# GD32M53x register map
File version: 1.0
CPU: CM33 r2p1, little endian, MPU, FPU, DSP, 4 interrupt priority bits
Registers are 32-bit, read-write, reset 0x0 unless marked. A register's access mark holds for its fields unless they carry their own. Offsets are from the block's base; [hi:lo] are bit positions; {n}, {i} and the like mark numbered series.

## GPTIMER0 — General purpose timer
Base 0x40016000
Same registers: GPTIMER1 0x40016100
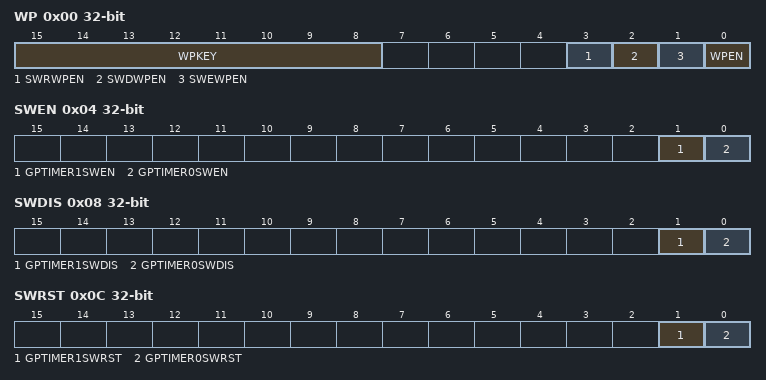
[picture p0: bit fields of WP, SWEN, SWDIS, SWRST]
0x00 WP access per field — Write-protect register
  [15:8] WPKEY wo — Write protection key
  [3] SWRWPEN rw — GPTIMERx_SWRST write protection enable
  [2] SWDWPEN rw — GPTIMERx_SWDIS write protection enable
  [1] SWEWPEN rw — GPTIMERx_SWEN write protection enable
  [0] WPEN rw — Register write protection enable
0x04 SWEN — Software enable register
  [1] GPTIMER1SWEN — GPTIMER1 counter software enable
  [0] GPTIMER0SWEN — GPTIMER0 counter software enable
0x08 SWDIS — Software disable register
  [1] GPTIMER1SWDIS — GPTIMER1 counter software disable
  [0] GPTIMER0SWDIS — GPTIMER0 counter software disable
0x0C SWRST — Software reset register
  [1] GPTIMER1SWRST — GPTIMER1 counter software reset
  [0] GPTIMER0SWRST — GPTIMER0 counter software reset
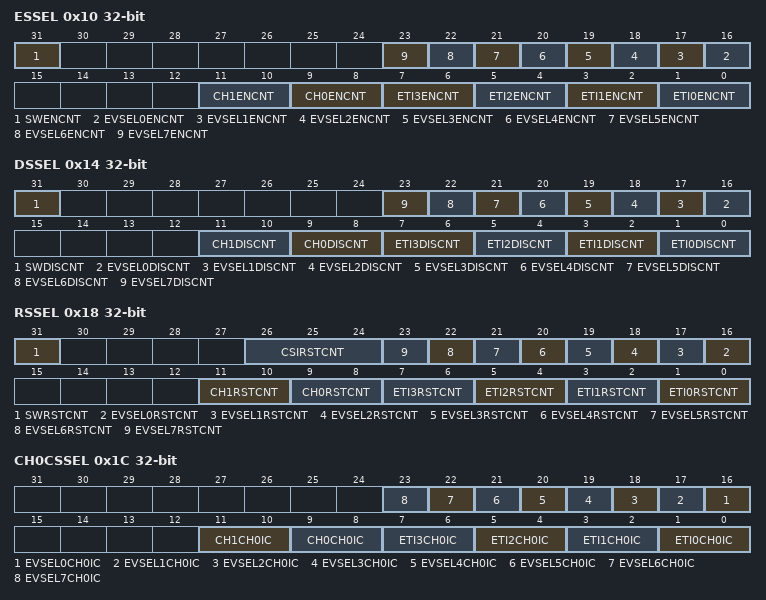
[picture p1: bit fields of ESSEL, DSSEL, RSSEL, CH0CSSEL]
0x10 ESSEL — Counter enable source selection register
  [31] SWENCNT — The software signal enable counter function enable
  [n+16] EVSEL{n}ENCNT (n=0..7) — The EVSEL{n} signal enable counter function enable
  [11:10] CH1ENCNT — The channel 1 signal edge enable counter function enable
  [9:8] CH0ENCNT — The channel 0 signal edge enable counter function enable
  [2n+1:2n] ETI{n}ENCNT (n=0..3) — The ETI{n} signal edge enable counter function enable
0x14 DSSEL — Counter disable source selection register
  [31] SWDISCNT — The software signal disable counter function enable
  [n+16] EVSEL{n}DISCNT (n=0..7) — The EVSEL{n} signal disable counter function enable
  [11:10] CH1DISCNT — The channel 1 signal edge disable counter function enable
  [9:8] CH0DISCNT — The channel 0 signal edge disable counter function enable
  [2n+1:2n] ETI{n}DISCNT (n=0..3) — The ETI{n} signal edge disable counter function enable
0x18 RSSEL — Counter reset source selection register
  [31] SWRSTCNT — The software signal reset counter function enable
  [26:24] CSIRSTCNT — The compares match, synchronous reset or input capture reset counter function enable
  [n+16] EVSEL{n}RSTCNT (n=0..7) — The EVSEL{n} signal reset counter function enable
  [11:10] CH1RSTCNT — The channel 1 signal edge reset counter function enable
  [9:8] CH0RSTCNT — The channel 0 signal edge reset counter function enable
  [2n+1:2n] ETI{n}RSTCNT (n=0..3) — The ETI{n} signal edge reset counter function enable
0x1C CH0CSSEL — Channel 0 capture source selection register
  [n+16] EVSEL{n}CH0IC (n=0..7) — The EVSEL{n} signal as the channel 0 input capture source enable
  [11:10] CH1CH0IC — The channel 1 signal edge as the channel 0 input capture source enable
  [9:8] CH0CH0IC — The channel 0 signal edge as the channel 0 input capture source enable
  [2n+1:2n] ETI{n}CH0IC (n=0..3) — The ETI{n} signal edge as the channel 0 input capture source enable
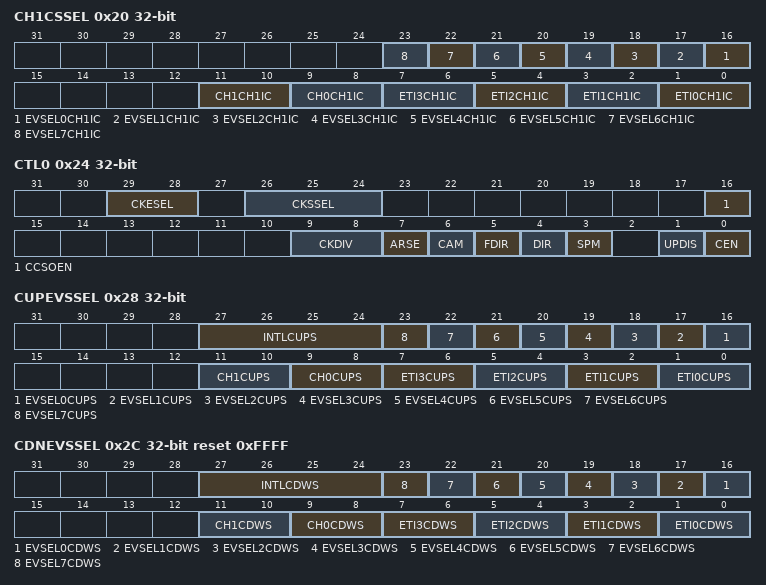
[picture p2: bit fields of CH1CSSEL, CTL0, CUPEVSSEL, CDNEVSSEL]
0x20 CH1CSSEL — Channel 1 capture source selection register
  [n+16] EVSEL{n}CH1IC (n=0..7) — The EVSEL{n} signal as the channel 1 input capture source enable
  [11:10] CH1CH1IC — The channel 1 signal edge as the channel 1 input capture source enable
  [9:8] CH0CH1IC — The channel 0 signal edge as the channel 1 input capture source enable
  [2n+1:2n] ETI{n}CH1IC (n=0..3) — The ETI{n} signal edge as the channel 1 input capture source enable
0x24 CTL0 — Control register 0
  [29:28] CKESEL — Effective edge selection when ETIx(x = 0, 1, 2, 3) is selected as the clock.
  [26:24] CKSSEL — Clock source selection
  [16] CCSOEN — The counter cycle synchronization signal output enable
  [9:8] CKDIV — Clock division
  [7] ARSE — Auto-reload shadow enable
  [6] CAM — Counter align mode selection
  [5] FDIR — Force the counting direction
  [4] DIR — Direction
  [3] SPM — Single pulse mode
  [1] UPDIS — Update event disable
  [0] CEN — Counter enable
0x28 CUPEVSSEL — Count up event source selection register
  [27:24] INTLCUPS — The input level as the count up event source function enable
  [n+16] EVSEL{n}CUPS (n=0..7) — The EVSEL{n} signal as the count up event source function enable
  [11:10] CH1CUPS — The channel 1 signal edge as the count up event source function enable
  [9:8] CH0CUPS — The channel 0 signal edge as the count up event source function enable
  [2n+1:2n] ETI{n}CUPS (n=0..3) — The ETI{n} signal edge as the count up event source function enable
0x2C CDNEVSSEL reset 0xFFFF — Count down event source selection register
  [27:24] INTLCDWS — The input level as the count down event source function enable
  [n+16] EVSEL{n}CDWS (n=0..7) — The EVSEL{n} signal as the count down event source function enable
  [11:10] CH1CDWS — The channel 1 signal edge as the count down event source function enable
  [9:8] CH0CDWS — The channel 0 signal edge as the count down event source function enable
  [2n+1:2n] ETI{n}CDWS (n=0..3) — The ETI{n} signal edge as the count down event source function enable
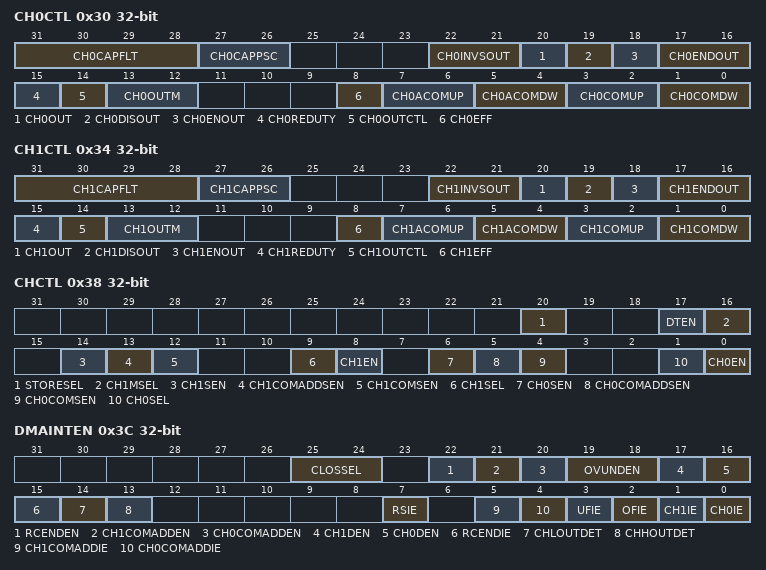
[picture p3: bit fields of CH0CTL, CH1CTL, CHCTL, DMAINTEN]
0x30 CH0CTL — Channel 0 control register
  [31:28] CH0CAPFLT — Channel 0 input capture filter control
  [27:26] CH0CAPPSC — Channel 0 input capture prescaler
  [22:21] CH0INVSOUT — Channel 0 invalid level setting when GTOC sends a stop output request
  [20] CH0OUT — Channel 0 output level selection when counter enable or disable.
  [19] CH0DISOUT — Channel 0 output level selection when counter disable
  [18] CH0ENOUT — Channel 0 output initial level selection when counter enable.
  [17:16] CH0ENDOUT — Channel 0 output level selection at the end of the period
  [15] CH0REDUTY — Channel 0 output level selection when counter release from 0% or 100% duty cycle mode
  [14] CH0OUTCTL — Channel 0 output control setting
  [13:12] CH0OUTM — Channel 0 output mode
  [8] CH0EFF — Channel 0 output control is effective or not when the end of the cycle and comparison match occur simultaneously.
  [7:6] CH0ACOMUP — Channel 0 additional compare match output level control when counter count up
  [5:4] CH0ACOMDW — Channel 0 additional compare match output level control when counter count down
  [3:2] CH0COMUP — Channel 0 compare match output level control when counter count up
  [1:0] CH0COMDW — Channel 0 compare match output level control when counter count down
0x34 CH1CTL — Channel 1 control register
  [31:28] CH1CAPFLT — Channel 1 input capture filter control
  [27:26] CH1CAPPSC — Channel 1 input capture prescaler
  [22:21] CH1INVSOUT — Channel 1 invalid level setting when GTOC sends a stop output request
  [20] CH1OUT — Channel 1 output level selection when counter enable or disable.
  [19] CH1DISOUT — Channel 1 output level selection when counter disable
  [18] CH1ENOUT — Channel 1 output initial level selection when counter enable.
  [17:16] CH1ENDOUT — Channel 1 output level selection at the end of the period
  [15] CH1REDUTY — Channel 1 output level selection when counter release from 0% or 100% duty cycle mode
  [14] CH1OUTCTL — Channel 1 output control setting
  [13:12] CH1OUTM — Channel 1 output mode
  [8] CH1EFF — Channel 1 output control is effective or not when the end of the cycle and comparison match occur simultaneously.
  [7:6] CH1ACOMUP — Channel 1 additional compare match output level control when counter count up
  [5:4] CH1ACOMDW — Channel 1 additional compare match output level control when counter count down
  [3:2] CH1COMUP — Channel 1 compare match output level control when counter count up
  [1:0] CH1COMDW — Channel 1 compare match output level control when counter count down
0x38 CHCTL — Channel control register
  [20] STORESEL — Stop output recovery time selection
  [17] DTEN — The insertion of the dead time enable
  [16] CH1MSEL — Channel 1 mode selection
  [14] CH1SEN — Channel 1 output shadow enable
  [13] CH1COMADDSEN — Channel 1 additional compare output shadow enable
  [12] CH1COMSEN — Channel 1 compare output shadow enable
  [9] CH1SEL — Channel 1 capture/compare selection
  [8] CH1EN — Channel 1 capture/compare enable
  [6] CH0SEN — Channel 0 output shadow enable
  [5] CH0COMADDSEN — Channel 0 additional compare output shadow enable
  [4] CH0COMSEN — Channel 0 compare output shadow enable
  [1] CH0SEL — Channel 0 capture/compare select
  [0] CH0EN — Channel 0 capture/compare enable
0x3C DMAINTEN — DMA and interrupt enable register
  [25:24] CLOSSEL — Closing output source selection from GTOC
  [22] RCENDEN — Repetition count end DMA request enable
  [21] CH1COMADDEN — Channel 1 additional compare DMA request enable
  [20] CH0COMADDEN — Channel 0 additional compare DMA request enable
  [19:18] OVUNDEN — Counter overflow / underflow DMA request enable
  [17] CH1DEN — Channel 1 capture / compare DMA request enable
  [16] CH0DEN — Channel 0 capture / compare DMA request enable
  [15] RCENDIE — Repetition count end interrupt enable
  [14] CHLOUTDET — Channel 0 and channel 1 simultaneously output low level output off detection enable
  [13] CHHOUTDET — Channel 0 and channel 1 simultaneously output high level output off detection enable
  [7] RSIE — Reset interrupt enable
  [5] CH1COMADDIE — Channel 1 additional compare interrupt enable
  [4] CH0COMADDIE — Channel 0 additional compare interrupt enable
  [3] UFIE — Counter underflow interrupt enable
  [2] OFIE — Counter overflow interrupt enable
  [1] CH1IE — Channel 1 capture/compare interrupt enable
  [0] CH0IE — Channel 0 capture/compare interrupt enable
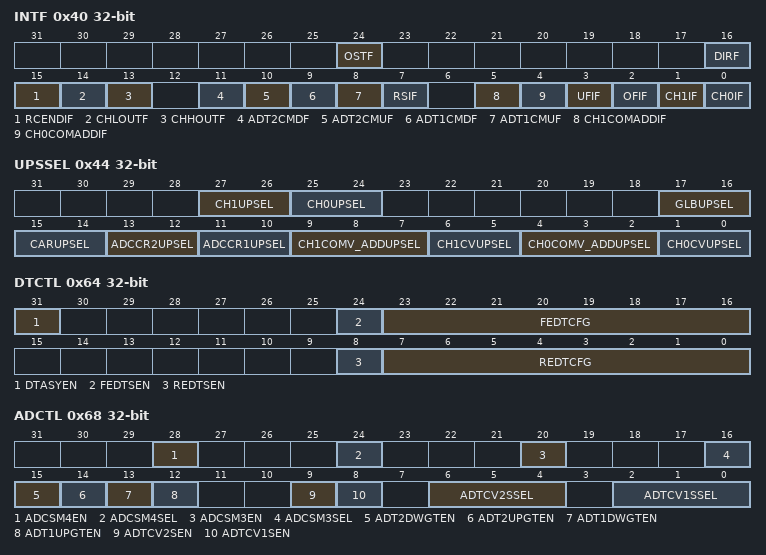
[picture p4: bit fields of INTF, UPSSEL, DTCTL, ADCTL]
0x40 INTF access per field — Interrupt flag register
  [24] OSTF ro — Output stop flag (Stop output source selected according to CLOSSEL[1:0] bit field)
  [16] DIRF ro — The counter direction flag
  [15] RCENDIF rw — Repetition count end interrupt flag
  [14] CHLOUTF ro — Channel 0 and channel 1 simultaneously output low level flag
  [13] CHHOUTF ro — Channel 0 and channel 1 simultaneously output high level flag
  [11] ADT2CMDF rw — ADTCV2[15:0] compare match (counting down only) flag.
  [10] ADT2CMUF rw — ADTCV2[15:0] compare match (counting up only) flag.
  [9] ADT1CMDF rw — ADTCV1[15:0] compare match (counting down only) flag.
  [8] ADT1CMUF rw — ADTCV1[15:0] compare match (counting up only) flag.
  [7] RSIF rw — Reset interrupt flag
  [5] CH1COMADDIF rw — Channel 1 additional compare interrupt flag.
  [4] CH0COMADDIF rw — Channel 0 additional compare interrupt flag.
  [3] UFIF rw — The counter underflow interrupt flag
  [2] OFIF rw — The counter overflow interrupt flag
  [1] CH1IF rw — Channel 1 capture/compare interrupt flag
  [0] CH0IF rw — Channel 0 capture/compare interrupt flag
0x44 UPSSEL — Update source selection register
  [27:26] CH1UPSEL — Channel 1 output mode update source selection.
  [25:24] CH0UPSEL — Channel 0 output mode update source selection.
  [17:16] GLBUPSEL — Global update mode update source selection.
  [15:14] CARUPSEL — The counter auto reload value update mode selection, used to set when the counter auto reload value will be automatically overloaded.
  [13:12] ADCCR2UPSEL — The ADC triggered comparison value 2 update mode selection.
  [11:10] ADCCR1UPSEL — The ADC triggered comparison value 1 update mode selection.
  [9:7] CH1COMV_ADDUPSEL — Channel 1 additional comparison value update mode selection.
  [6:5] CH1CVUPSEL — Channel 1 capture/compare value update mode selection.
  [4:2] CH0COMV_ADDUPSEL — Channel 0 additional comparison value update mode selection.
  [1:0] CH0CVUPSEL — Channel 0 capture/compare value update mode selection.
0x48 CNT — Counter register
  [15:0] CNT — This bit-field indicates the current counter value. Writing to this bit-field can change the value of the counter.
0x4C PSC — Prescaler register
  [15:0] PSC — Prescaler value of the counter clock
0x50 CAR — Counter auto reload register
  [15:0] CARL — Counter auto reload value
0x54 CH0CV — Channel 0 capture/compare value register
  [15:0] CH0VAL — Capture/compare value of channel 0
0x58 CH1CV — Channel 1 capture/compare value register
  [15:0] CH1VAL — Capture/compare value of channel 1
0x5C CH0COMV_ADD — Channel 0 additional compare value register
  [15:0] CH0COMVAL_ADD — Additional compare value of channel 0
0x60 CH1COMV_ADD — Channel 1 additional compare value register
  [15:0] CH1COMVAL_ADD — Additional compare value of channel 1
0x64 DTCTL — Dead-time control register
  [31] DTASYEN — Dead time asymmetric mode enable
  [24] FEDTSEN — The falling edge dead time shadow register is enabled.
  [23:16] FEDTCFG — The falling edge dead time configuration
  [8] REDTSEN — The rising edge dead time shadow register enable
  [7:0] REDTCFG — The rising edge dead time configuration
0x68 ADCTL — ADC trigger control register
  [28] ADCSM4EN — ADCSM4 pin output enable
  [24] ADCSM4SEL — Select the ADC trigger source connected to ADCSM4 pin
  [20] ADCSM3EN — ADCSM3 pin output enable
  [16] ADCSM3SEL — Select the ADC trigger source connected to ADCSM3 pin
  [15] ADT2DWGTEN — The ADTCV2[15:0] comparison match (count down only) generate trigger enable
  [14] ADT2UPGTEN — The ADTCV2[15:0] comparison match (count up only) generate trigger enable
  [13] ADT1DWGTEN — The ADTCV1[15:0] comparison match (count down only) generate trigger enable
  [12] ADT1UPGTEN — The ADTCV1[15:0] comparison match (count up only) generate trigger enable
  [9] ADTCV2SEN — The ADTCV2[15:0] shadow register enable
  [8] ADTCV1SEN — The ADTCV1[15:0] shadow register enable
  [6:4] ADTCV2SSEL — The ADC conversion request skipping source selection and the trigger signal generated by ADTCV2[15:0]
  [2:0] ADTCV1SSEL — The ADC conversion request skipping source selection and the trigger signal generated by ADTCV1[15:0]
0x6C ADCCR1 — ADC trigger compare value register 1
  [15:0] ADTCV1 — The ADC trigger compare value 1
0x70 ADCCR2 — ADC trigger compare value register 2
  [15:0] ADTCV2 — The ADC trigger compare value 2
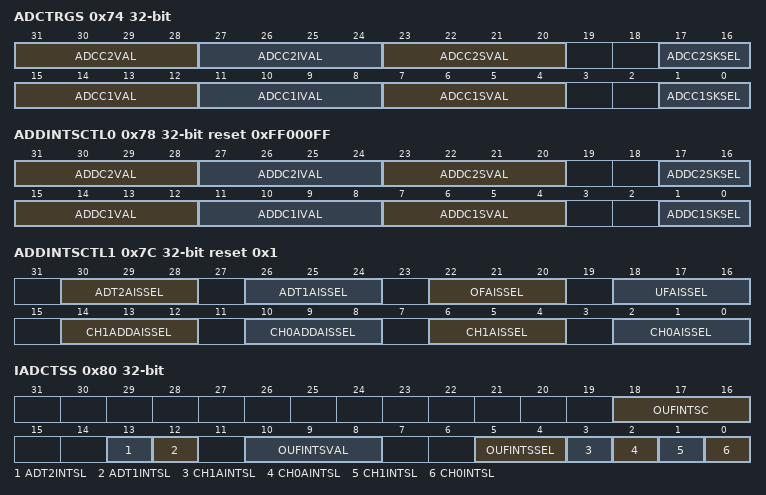
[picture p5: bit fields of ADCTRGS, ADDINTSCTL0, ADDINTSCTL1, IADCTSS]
0x74 ADCTRGS — ADC trigger skipping register
  [31:28] ADCC2VAL — This bit-field indicates the current ADC skipping counter 2 value.
  [27:24] ADCC2IVAL — The ADC skipping counter 2 Initial value
  [23:20] ADCC2SVAL — The ADC skipping counter 2 skipping value
  [17:16] ADCC2SKSEL — The ADC skipping counter 2 skipping source selection
  [15:12] ADCC1VAL — This bit-field indicates the current ADC skipping counter 1 value.
  [11:8] ADCC1IVAL — The ADC skipping counter 1 Initial value
  [7:4] ADCC1SVAL — The ADC skipping counter 1 skipping value
  [1:0] ADCC1SKSEL — The ADC skipping counter 1 skipping source selection
0x78 ADDINTSCTL0 reset 0xFF000FF — Additional interrupt skipping control register 0
  [31:28] ADDC2VAL — This bit-field indicates the current additional interrupt skipping counter 2 value.
  [27:24] ADDC2IVAL — The additional interrupt skipping counter 2 Initial value
  [23:20] ADDC2SVAL — The additional interrupt skipping counter 2 skipping value
  [17:16] ADDC2SKSEL — The additional interrupt skipping counter 2 skipping source selection
  [15:12] ADDC1VAL — This bit-field indicates the current additional interrupt skipping counter 1 value.
  [11:8] ADDC1IVAL — The additional interrupt skipping counter 1 Initial value
  [7:4] ADDC1SVAL — The additional interrupt skipping counter 1 skipping value
  [1:0] ADDC1SKSEL — The additional interrupt skipping counter 1 skipping source selection
0x7C ADDINTSCTL1 reset 0x1 — Additional interrupt skipping control register 1
  [30:28] ADT2AISSEL — The trigger signal generated by ADTCV2[15:0] additional interrupt skipping function selection.
  [26:24] ADT1AISSEL — The trigger signal generated by ADTCV1[15:0] additional interrupt skipping function selection.
  [22:20] OFAISSEL — Overflow additional interrupt skipping function selection.
  [18:16] UFAISSEL — Underflow additional interrupt skipping function selection.
  [14:12] CH1ADDAISSEL — The channel 1 additional value compare match additional interrupt skipping function selection.
  [10:8] CH0ADDAISSEL — The channel 0 additional value compare match additional interrupt skipping function selection.
  [6:4] CH1AISSEL — The channel 1 input capture/compare match additional interrupt skipping function selection.
  [2:0] CH0AISSEL — The channel 0 input capture/compare match additional interrupt skipping function selection.
0x80 IADCTSS — Interrupt and ADC trigger signal skipping register
  [18:16] OUFINTSC — Overflow / underflow interrupt skipping counter
  [13] ADT2INTSL — The trigger signal generated by ADTCV2[15:0] interrupt skipping link
  [12] ADT1INTSL — The trigger signal generated by ADTCV1[15:0] interrupt skipping link
  [10:8] OUFINTSVAL — The number of overflow / underflow interrupt skipping value
  [5:4] OUFINTSSEL — Overflow / underflow interrupt skip selection
  [3] CH1AINTSL — The channel 1 additional value compare match interrupt skipping link
  [2] CH0AINTSL — The channel 0 additional value compare match interrupt skipping link
  [1] CH1INTSL — The channel 1 input capture/compare match interrupt skipping link
  [0] CH0INTSL — The channel 0 input capture/compare match interrupt skipping link
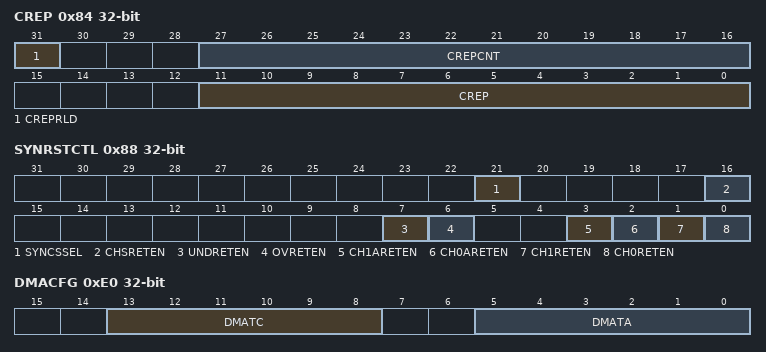
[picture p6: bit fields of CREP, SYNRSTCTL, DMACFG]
0x84 CREP access per field — Counter repetition register
  [31] CREPRLD rw — The repeat counter is loaded immediately
  [27:16] CREPCNT ro — Repeat counter current value
  [11:0] CREP rw — Counter repetition value
0x88 SYNRSTCTL — Synchronous reset control register
  [21] SYNCSSEL — GPTIMER synchronization control set selection
  [16] CHSRETEN — Channel input as the other GPTIMER synchronization reset source enable
  [7] UNDRETEN — Underflow as the other GPTIMER synchronization reset source enable
  [6] OVRETEN — Overflow as the other GPTIMER synchronization reset source enable
  [3] CH1ARETEN — Channel 1 additional value compare match as the other GPTIMER synchronization reset source enable
  [2] CH0ARETEN — Channel 0 additional value compare match as the other GPTIMER synchronization reset source enable
  [1] CH1RETEN — Channel 1 compare match / input capture as the other GPTIMER synchronization reset source enable
  [0] CH0RETEN — Channel 0 compare match / input capture as the other GPTIMER synchronization reset source enable
0xE0 DMACFG — DMA configuration register
  [13:8] DMATC — DMA transfer count
  [5:0] DMATA — DMA transfer access start address
0xE4 DMATB — DMA transfer buffer register
  [15:0] DMATB — DMA transfer buffer
0xFC CFG — Configuration register
  [1] CHVSEL — Write CHxVAL register selection
